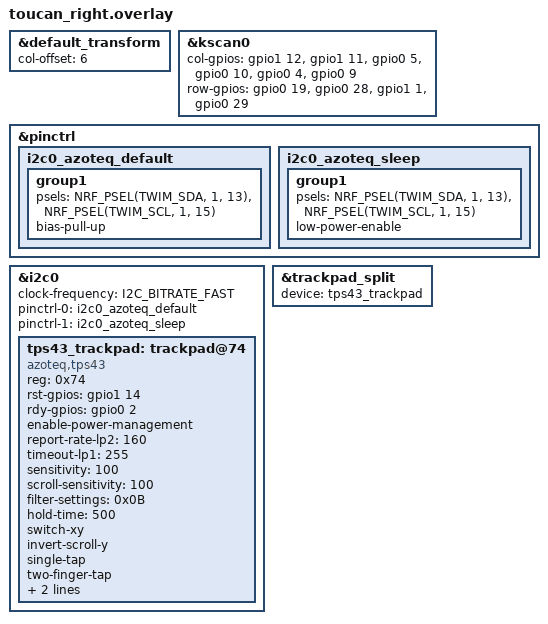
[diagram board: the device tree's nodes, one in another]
#include "toucan.dtsi"
#include <input/processors.dtsi>
#include <dt-bindings/zmk/input_transform.h>

/*
 * 右半 = split peripheral，持有實體觸控板感測器。
 *
 * 2026-09-03：Cirque Pinnacle (SPI0) → Azoteq TPS43 (I2C0 @0x74)。
 * 這台是 toucan2，硬體跟 repo 原本 fork 的 toucan1 不同，詳細比較與腳位
 * 對撞表見 config/west.yml 的 zmk_driver_azoteq 那段註解。
 *
 * ⚠️ 不要在這裡把 xiao_i2c 設 disabled——它是 &i2c0 的 label 別名，關掉
 *    等於關掉觸控板的匯流排。（左半才需要關：那邊 spi0 給 nice_view 用，
 *    而 nRF52840 的 SPIM0 / TWIM0 是同一顆周邊，兩者不能並存。）
 */

&default_transform {
    col-offset = <6>;
};

&kscan0 {
    col-gpios
    = <&gpio1 12 GPIO_ACTIVE_HIGH>
    , <&gpio1 11 GPIO_ACTIVE_HIGH>
    , <&gpio0 5 GPIO_ACTIVE_HIGH>
    , <&gpio0 10 GPIO_ACTIVE_HIGH>
    , <&gpio0 4 GPIO_ACTIVE_HIGH>
    , <&gpio0 9 GPIO_ACTIVE_HIGH>
    ;

    row-gpios
    = <&gpio0 19 (GPIO_ACTIVE_HIGH | GPIO_PULL_DOWN)>
    , <&gpio0 28 (GPIO_ACTIVE_HIGH | GPIO_PULL_DOWN)>
    , <&gpio1 1 (GPIO_ACTIVE_HIGH | GPIO_PULL_DOWN)>
    , <&gpio0 29 (GPIO_ACTIVE_HIGH | GPIO_PULL_DOWN)>
    ;
};

&pinctrl {
    i2c0_azoteq_default: i2c0_azoteq_default {
        group1 {
            psels = <NRF_PSEL(TWIM_SDA, 1, 13)>,
                    <NRF_PSEL(TWIM_SCL, 1, 15)>;
            bias-pull-up;
        };
    };

    i2c0_azoteq_sleep: i2c0_azoteq_sleep {
        group1 {
            psels = <NRF_PSEL(TWIM_SDA, 1, 13)>,
                    <NRF_PSEL(TWIM_SCL, 1, 15)>;
            low-power-enable;
        };
    };
};

&i2c0 {
    status = "okay";
    clock-frequency = <I2C_BITRATE_FAST>;
    pinctrl-0 = <&i2c0_azoteq_default>;
    pinctrl-1 = <&i2c0_azoteq_sleep>;
    pinctrl-names = "default", "sleep";

    /*
     * 數值基準 = beekeeb/zmk-keyboard-toucan2 的原廠設定（同一塊板子、同一
     * 顆感測器），只有「手勢開關」按這個 repo 既有的設計調整，見下方。
     */
    tps43_trackpad: trackpad@74 {
        compatible = "azoteq,tps43";
        reg = <0x74>;
        status = "okay";

        rst-gpios = <&gpio1 14 GPIO_ACTIVE_HIGH>;
        rdy-gpios = <&gpio0 2 GPIO_ACTIVE_HIGH>;

        /*
         * ── 省電與「碰下去要等多久才動」──────────────────────────────
         *
         * 兩套機制完全獨立，別搞混：
         *
         * (A) ZMK 這一側：`enable-power-management` 讓驅動訂閱 ZMK 的
         *     activity 狀態。**沒設 `idle-sleep` 的話，ZMK IDLE（本 repo
         *     30 秒）不會碰觸控板**，只有 ZMK SLEEP（CONFIG_ZMK_IDLE_SLEEP_
         *     TIMEOUT，本 repo 20 分鐘）才真的 suspend。驅動自己沒有另外
         *     的自動 suspend 計時器。⇒ 平常打字時這一套幾乎不會觸發。
         *
         * (B) 感測器自己的狀態機（**日常感受到的延遲來自這裡**）：
         *       ACTIVE -> IDLE-TOUCH -> IDLE -> LP1 -> LP2
         *     每一階有自己的掃描間隔（report-rate-*），停止觸摸後依
         *     timeout-* 逐階往下掉。**手指放上去到游標會動的最壞延遲，
         *     就等於它當下那一階的 report rate。**
         *
         * 調整史：2026-09-03 把 beekeeb 原本的 `report-rate-lp2 = <640>`
         * 改成 240；2026-09-17 改成 160、timeout-lp1 9 -> 3。
         *
         * ⚠️ **2026-09-18 更正：beekeeb 註解裡的 µA 數字抄錯欄位，前面幾次
         *    調整都建立在高估 7 倍的成本上。** 他寫「640 ms ≈ 55µA /
         *    160 ms ≈ 174µA」，那是 IQS5xx-B000 datasheet §10.2.5 的**掃全板**
         *    那一欄。但 LP1/LP2 掃全板還是掃 ALP（單一低功耗接近通道）是可設
         *    的——ALPChannelSetup0 (0x0658) bit4，0 = LP 用全板 / 1 = 用 ALP。
         *    而 Azoteq 自家模組 datasheet（TPS43/TPS65 Standard Trackpad
         *    Module v1.06）Table 5.1 量到的是 **Low Power Current typ 23 µA**，
         *    註腳寫明「LP2 Report Rate set to 160ms」。對照 §10.2.5 的 160 ms
         *    那列：掃全板 174µA (IQS572) / 243µA (IQS550)，ALP 21~25µA
         *    ⇒ **出廠設定就是 ALP**，LP 電流比原本以為的小一個數量級。
         *    （那 23 µA 是在 TPS65 上量的，我們是 TPS43；同系列同一張電源表，
         *    要 100% 確定得讀 0x0658 bit4，需要一次性 debug 韌體，沒做。）
         *
         * 修正後的電流（§10.2.5，IQS572 欄）：
         *
         *   掃描間隔   全板（ACTIVE / IDLE-TOUCH / IDLE）   ALP（LP1 / LP2）
         *      13 ms        ~2.3 mA                            —
         *      50 ms        ~550 µA                            —
         *      80 ms         346 µA                          ~45 µA
         *     160 ms         174 µA                          ~23 µA
         *     640 ms          55 µA                           ~7 µA
         *
         * ⇒ **停在 LP1（80 ms）只比 LP2（160 ms）多 ~20µA**，8 小時約
         *   0.2 mAh。所以 2026-09-18 直接 timeout-lp1 = 255 = 永不進 LP2。
         *
         * 為什麼 80 ms 就夠、不用再往下追：ALP 是**接近感應**，偵測的是手
         * 靠近而不是碰到。手從鍵盤移到板子約 200~300 ms，80 ms 的週期等於
         * 手還在半空中就醒了 ⇒ 主觀接近零延遲。之前 240 ms 會卡，正是因為
         * 週期吃掉整段接近時間、沒有提前量。
         *
         * 各階數值（沒在這裡寫的欄位就是晶片預設——驅動 binding 寫明
         * 「Only written if explicitly set」；預設值出自驅動自己的 register
         * dump，見 zmk_driver_azoteq 的 doc/develop.md）：
         *
         *   ACTIVE      13 ms   停 5 秒
         *   IDLE-TOUCH  50 ms   停 60 秒
         *   IDLE        50 ms   停 10 秒
         *   LP1         80 ms   停 timeout-lp1 x 20 秒（本檔 255 = 永不）
         *   LP2        160 ms   現在到不了，只有把 timeout-lp1 調回有限值才會用到
         *
         * ⇒ 手指離開之後：5 秒掉到 IDLE（50 ms）、15 秒掉到 LP1（80 ms），
         *   然後就停在 LP1，直到 ZMK SLEEP（20 分鐘）把整顆 suspend 掉。
         *
         * ⚠️ 唯一沒有實證的地方：state diagram 裡 LP1 -> LP2 這個 timeout 的
         *    動作是「reseed LP channel」。永不 timeout 等於那個週期性 reseed
         *    不會發生（ALP 的 LTA 追蹤和 ref-update-time 仍在跑，理論上夠）。
         *    **症狀會是「用久了要碰很用力才醒」**，真的出現就把 timeout-lp1
         *    設回 <45>（= 15 分鐘），讓它偶爾 reseed 一次。
         *
         * 還想更快（目前判斷不需要）：report-rate-lp1 = <40> 約 ~90µA、
         * <20> 約 ~175µA。再往下才是改驅動做「打字時把感測器踢回 ACTIVE」
         * （SystemConfig0 bit7 MANUAL_CONTROL + SystemControl0 bit2-0
         * MODE_SELECT）——以修正後的電流看**不值得**，那套頂多省 20~40µA
         * 卻要長期維護一份 driver fork，而且只看得到右半的按鍵。
         */
        enable-power-management;
        report-rate-lp2 = <160>;   /* timeout-lp1=255 時到不了，留著當 fallback */
        timeout-lp1 = <255>;       /* 255 = 永不掉進 LP2（datasheet 4.2） */
        /* 設了 idle-sleep 會讓 ZMK IDLE（30 秒）就 suspend 觸控板，
         * 省電但「30 秒沒打字就要等醒來」，不建議。 */
        // idle-sleep;

        /*
         * ── 手感 ──────────────────────────────────────────────────────
         * sensitivity        觸控靈敏度 %，binding 預設 100
         * scroll-sensitivity 滾動靈敏度 %，**binding 預設是 50，不是 100**
         *                    ——這行不是冗餘，拿掉行為會變
         * filter-settings    座標濾波。0x0F=全開（最平滑、延遲最高，binding
         *                    預設）/ 0x0B=IIR+MAV+ALP 動態 IIR（平衡，現用）
         *                    / 0x03=只有 IIR+MAV / 0x01=只有 IIR（最低延遲）
         *                    / 0x00=不濾（原始資料，會抖）
         *                    覺得「游標黏黏的、跟不上手」就往 0x03 或 0x01 調。
         * hold-time          press-and-hold 的判定時間（ms）。目前沒開那個
         *                    手勢，所以這行暫時不影響任何行為。
         */
        sensitivity = <100>;
        scroll-sensitivity = <100>;
        filter-settings = <0x0B>;
        hold-time = <500>;

        /*
         * ── 還有這些旋鈕，需要再打開（完整清單見驅動的
         *    dts/bindings/input/azoteq,tps43-common.yaml）──────────────
         *
         * 點擊手感：
         *   tap-time = <ms>          點擊的最長按壓時間
         *   tap-distance = <px>      點擊時容許的最大位移（手抖會誤判成拖曳時調大）
         *
         * 追蹤與解析度：
         *   report-rate-active = <ms>   移動中的回報間隔（越小越跟手、越耗電）
         *   x-resolution / y-resolution 觸控板解析度
         *   filter-dynamic-bottom / -lower / -upper
         *                               低速時的濾波強度與速度門檻，
         *                               「慢慢移很鈍」就是調這組
         *
         * 其他省電階段（晶片預設值見上面「省電與碰下去要等多久才動」的表）：
         *   report-rate-idle / -idle-touch / -lp1
         *   timeout-active / -idle-touch / -idle
         *
         * 手勢細節（要先開對應的手勢才有意義）：
         *   scroll-initial-distance / scroll-angle
         *   zoom-initial-distance / zoom-consecutive-distance / zoom-sensitivity
         *   swipe-initial-distance / -initial-time / -angle
         *   swipe-consecutive-distance / -consecutive-time
         *
         * ATI（自動調校，碰到誤觸或不靈敏才動，動錯會整個壞掉）：
         *   ati-target / ref-drift-limit / reati-lower-limit /
         *   reati-upper-limit / max-count-limit / ati-retry-time /
         *   ref-update-time
         */

        /*
         * ── 方位 ──────────────────────────────────────────────────────
         * 照抄 beekeeb toucan2：感測器是轉過的，沒有 switch-xy 的話 X / Y
         * 會對調。
         *
         * ⚠️ 實機如果方向不對，只有三個旋鈕，依序試：
         *   1. 這裡的 switch-xy（拿掉 = X/Y 不對調）
         *   2. 這裡加 invert-x / invert-y
         *   3. toucan-trackpad.dtsi 各滾動鏈的 INPUT_TRANSFORM_*_INVERT
         *      ——那幾個是當年配合 Cirque 的方位調出來的，換感測器之後
         *      很可能要跟著翻。
         */
        switch-xy;
        invert-scroll-y;

        /*
         * ── 手勢 ──────────────────────────────────────────────────────
         * TPS43 的手勢是「感測器內建」的（devicetree flag 直接進硬體），
         * 不是 ZMK input processor——這跟 Cirque 完全不同，Cirque 那邊
         * 所有手勢都是靠 processor 疊出來的。
         *
         * 目前只開兩個「點擊」，刻意跟這個 repo 既有的設計對齊：
         *
         *   single-tap      點一下 = 左鍵。等同 Cirque 時代的行為，會被
         *                   toucan.keymap 的 &zip_button_behaviors 攔下來
         *                   換成 &pad_tap_l。
         *   two-finger-tap  兩指點 = 右鍵 → &pad_tap_r。Cirque 沒有，
         *                   但語意一致，白賺的。
         *
         * 以下刻意「不」開，理由都在既有設計裡：
         *
         *   press-and-hold  = 按住拖曳。使用者刻意讓「pad 單獨拖曳變成
         *                     不可能」（見 toucan.keymap 檔頭的
         *                     zip_button_behaviors 說明），要拖曳是按住
         *                     PAD 層的 LCLK 再移動。開了會打架。
         *   scroll          = 硬體雙指滾動。**2026-09-08 打開來實測中。**
         *                     ⚠️ 跟這個 repo 既有的滾動設計並存：本來的滾動是
         *                     「層 + 單指拖曳 + 三檔調速」（SCRL / SCR- / SCR /
         *                     SCR+，用 zip_xy_to_scroll_mapper）。在那三層上做
         *                     雙指滾動會被處理兩次（硬體自己送 scroll，
         *                     mapper 又把同一段 XY 轉成 scroll），會過快。
         *                     ⚠️ 已知症狀：捲到一半卡住、游標跳位。那是手勢中
         *                     途被中斷 —— 第二根手指的觸壓掉到門檻以下、或兩指
         *                     移動方向超出 scroll-angle 的容許錐角，手勢就會
         *                     abort，剩下那根手指改被當成「移動游標」上報。
         *                     要救先動這兩個（都不是省電延遲那組）：
         *                       scroll-angle  往大調（30 -> 45），角度容許放寬
         *                       sensitivity   往上調，手指輕一點也不會掉偵測
         *                     其次是 timeout-active 拉長 / report-rate-idle-touch
         *                     調快——慢速穩定捲動時掉進 IDLE-TOUCH 會讓回報變慢，
         *                     再回到 ACTIVE 時一次補上累積位移，也會看到跳動。
         *                     ⚠️ 另外 two-finger-tap（右鍵）也是兩指，短促的雙指
         *                     滑動有機會被判成 tap 而誤觸右鍵，測的時候留意。
         *   zoom            = 雙指縮放，需要 zmk-input-zoom 的 zip_zoom_mapper
         *                     接在 listener 上（模組已在 west.yml 拉進來）。
         *   three-finger-swipe = 三指滑動切桌面，需要 swipe_button_mapper。
         *
         * 全部都是一行的事，等基本游標確認正常再逐個加。
         */
        single-tap;
        two-finger-tap;
        // press-and-hold;
        scroll;
        scroll-angle = <30>;
        // zoom;
        // three-finger-swipe;
        // three-finger-swipe-throttle-ms = <1200>;
    };
};

/*
 * 把感測器綁到 input-split 的 proxy 上。對側（central）那份在
 * toucan-trackpad.dtsi，reg 必須一致（都是 0）。
 */
&trackpad_split {
    device = <&tps43_trackpad>;
};
